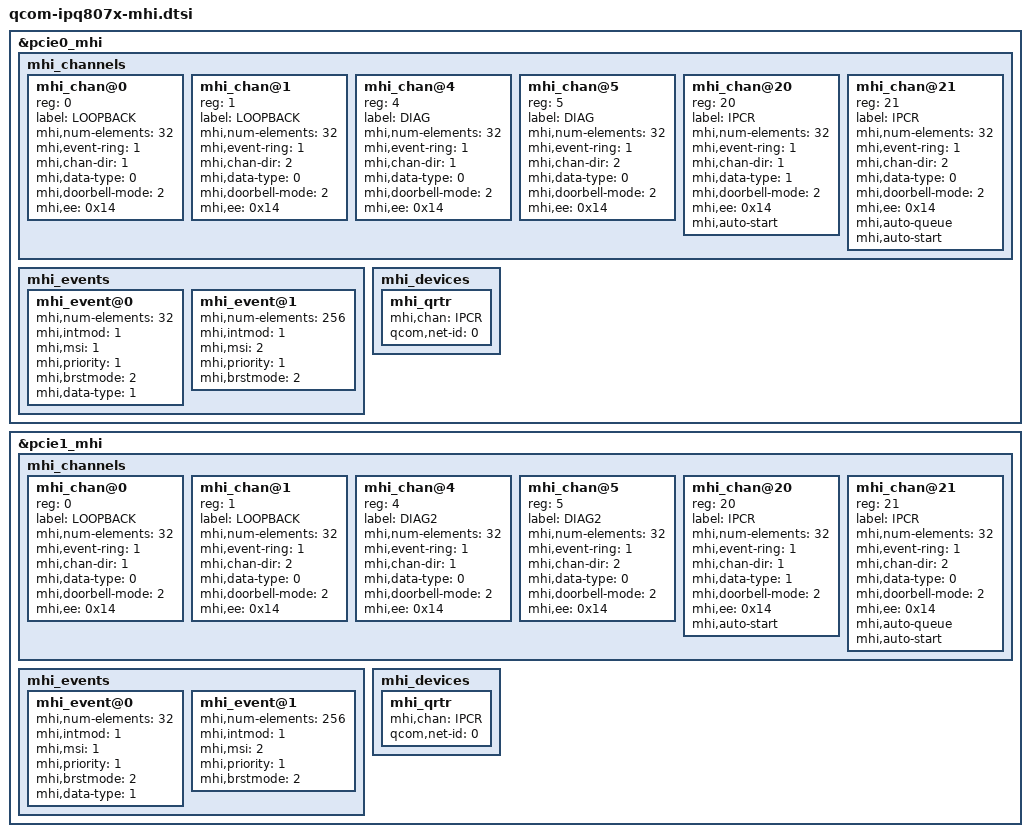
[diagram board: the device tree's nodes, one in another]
/*
 * Copyright (c) 2017-2020, The Linux Foundation. All rights reserved.
 *
 * Permission to use, copy, modify, and/or distribute this software for any
 * purpose with or without fee is hereby granted, provided that the above
 * copyright notice and this permission notice appear in all copies.
 *
 * THE SOFTWARE IS PROVIDED "AS IS" AND THE AUTHOR DISCLAIMS ALL WARRANTIES
 * WITH REGARD TO THIS SOFTWARE INCLUDING ALL IMPLIED WARRANTIES OF
 * MERCHANTABILITY AND FITNESS. IN NO EVENT SHALL THE AUTHOR BE LIABLE FOR
 * ANY SPECIAL, DIRECT, INDIRECT, OR CONSEQUENTIAL DAMAGES OR ANY DAMAGES
 * WHATSOEVER RESULTING FROM LOSS OF USE, DATA OR PROFITS, WHETHER IN AN
 * ACTION OF CONTRACT, NEGLIGENCE OR OTHER TORTIOUS ACTION, ARISING OUT OF
 * OR IN CONNECTION WITH THE USE OR PERFORMANCE OF THIS SOFTWARE.
 */

&pcie0_mhi {
	#address-cells = <1>;
	#size-cells = <0>;

	mhi_channels {
		#address-cells = <1>;
		#size-cells = <0>;

		mhi_chan@0 {
			reg = <0>;
			label = "LOOPBACK";
			mhi,num-elements = <32>;
			mhi,event-ring = <1>;
			mhi,chan-dir = <1>;
			mhi,data-type = <0>;
			mhi,doorbell-mode = <2>;
			mhi,ee = <0x14>;
		};

		mhi_chan@1 {
			reg = <1>;
			label = "LOOPBACK";
			mhi,num-elements = <32>;
			mhi,event-ring = <1>;
			mhi,chan-dir = <2>;
			mhi,data-type = <0>;
			mhi,doorbell-mode = <2>;
			mhi,ee = <0x14>;
		};

		mhi_chan@4 {
			reg = <4>;
			label = "DIAG";
			mhi,num-elements = <32>;
			mhi,event-ring = <1>;
			mhi,chan-dir = <1>;
			mhi,data-type = <0>;
			mhi,doorbell-mode = <2>;
			mhi,ee = <0x14>;
		};

		mhi_chan@5 {
			reg = <5>;
			label = "DIAG";
			mhi,num-elements = <32>;
			mhi,event-ring = <1>;
			mhi,chan-dir = <2>;
			mhi,data-type = <0>;
			mhi,doorbell-mode = <2>;
			mhi,ee = <0x14>;
		};

		mhi_chan@20 {
			reg = <20>;
			label = "IPCR";
			mhi,num-elements = <32>;
			mhi,event-ring = <1>;
			mhi,chan-dir = <1>;
			mhi,data-type = <1>;
			mhi,doorbell-mode = <2>;
			mhi,ee = <0x14>;
			mhi,auto-start;
		};

		mhi_chan@21 {
			reg = <21>;
			label = "IPCR";
			mhi,num-elements = <32>;
			mhi,event-ring = <1>;
			mhi,chan-dir = <2>;
			mhi,data-type = <0>;
			mhi,doorbell-mode = <2>;
			mhi,ee = <0x14>;
			mhi,auto-queue;
			mhi,auto-start;
		};
	};

	mhi_events {

		#address-cells = <1>;
		#size-cells = <0>;

		mhi_event@0 {
			mhi,num-elements = <32>;
			mhi,intmod = <1>;
			mhi,msi = <1>;
			mhi,priority = <1>;
			mhi,brstmode = <2>;
			mhi,data-type = <1>;
		};

		mhi_event@1 {
			mhi,num-elements = <256>;
			mhi,intmod = <1>;
			mhi,msi = <2>;
			mhi,priority = <1>;
			mhi,brstmode = <2>;
		};
	};

	mhi_devices {
		#address-cells = <1>;
		#size-cells = <0>;
		mhi_qrtr {
			mhi,chan = "IPCR";
			qcom,net-id = <0>;
		};
	};

};

&pcie1_mhi {
	#address-cells = <1>;
	#size-cells = <0>;

	mhi_channels {
		#address-cells = <1>;
		#size-cells = <0>;
		mhi_chan@0 {
			reg = <0>;
			label = "LOOPBACK";
			mhi,num-elements = <32>;
			mhi,event-ring = <1>;
			mhi,chan-dir = <1>;
			mhi,data-type = <0>;
			mhi,doorbell-mode = <2>;
			mhi,ee = <0x14>;
		};

		mhi_chan@1 {
			reg = <1>;
			label = "LOOPBACK";
			mhi,num-elements = <32>;
			mhi,event-ring = <1>;
			mhi,chan-dir = <2>;
			mhi,data-type = <0>;
			mhi,doorbell-mode = <2>;
			mhi,ee = <0x14>;
		};

		mhi_chan@4 {
			reg = <4>;
			label = "DIAG2";
			mhi,num-elements = <32>;
			mhi,event-ring = <1>;
			mhi,chan-dir = <1>;
			mhi,data-type = <0>;
			mhi,doorbell-mode = <2>;
			mhi,ee = <0x14>;
		};

		mhi_chan@5 {
			reg = <5>;
			label = "DIAG2";
			mhi,num-elements = <32>;
			mhi,event-ring = <1>;
			mhi,chan-dir = <2>;
			mhi,data-type = <0>;
			mhi,doorbell-mode = <2>;
			mhi,ee = <0x14>;
		};

		mhi_chan@20 {
			reg = <20>;
			label = "IPCR";
			mhi,num-elements = <32>;
			mhi,event-ring = <1>;
			mhi,chan-dir = <1>;
			mhi,data-type = <1>;
			mhi,doorbell-mode = <2>;
			mhi,ee = <0x14>;
			mhi,auto-start;
		};

		mhi_chan@21 {
			reg = <21>;
			label = "IPCR";
			mhi,num-elements = <32>;
			mhi,event-ring = <1>;
			mhi,chan-dir = <2>;
			mhi,data-type = <0>;
			mhi,doorbell-mode = <2>;
			mhi,ee = <0x14>;
			mhi,auto-queue;
			mhi,auto-start;
		};
	};

	mhi_events {
		#address-cells = <1>;
		#size-cells = <0>;
		mhi_event@0 {
			mhi,num-elements = <32>;
			mhi,intmod = <1>;
			mhi,msi = <1>;
			mhi,priority = <1>;
			mhi,brstmode = <2>;
			mhi,data-type = <1>;
		};

		mhi_event@1 {
			mhi,num-elements = <256>;
			mhi,intmod = <1>;
			mhi,msi = <2>;
			mhi,priority = <1>;
			mhi,brstmode = <2>;
		};
	};

	mhi_devices {
		#address-cells = <1>;
		#size-cells = <0>;
		mhi_qrtr {
			mhi,chan = "IPCR";
			qcom,net-id = <0>;
		};
	};
};
